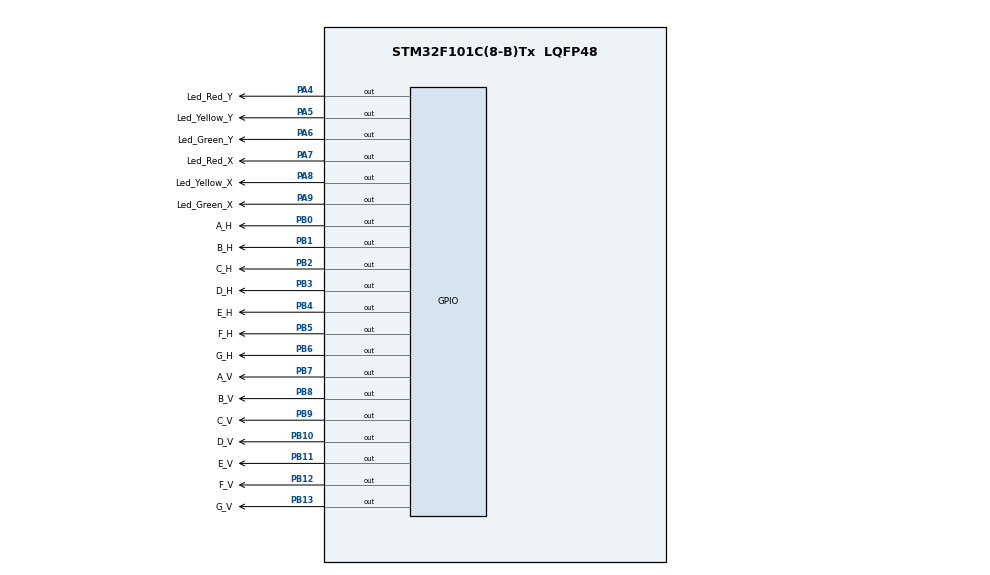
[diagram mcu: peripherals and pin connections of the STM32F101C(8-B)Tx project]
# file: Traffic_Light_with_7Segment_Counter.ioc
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Mcu.Family=STM32F1
Mcu.Name=STM32F101C(8-B)Tx
Mcu.Package=LQFP48
NVIC.PriorityGroup=NVIC_PRIORITYGROUP_4
PA4.GPIO_Label=Led_Red_Y
PA4.Signal=GPIO_Output
PA5.GPIO_Label=Led_Yellow_Y
PA5.Signal=GPIO_Output
PA6.GPIO_Label=Led_Green_Y
PA6.Signal=GPIO_Output
PA7.GPIO_Label=Led_Red_X
PA7.Signal=GPIO_Output
PA8.GPIO_Label=Led_Yellow_X
PA8.Signal=GPIO_Output
PA9.GPIO_Label=Led_Green_X
PA9.Signal=GPIO_Output
PB0.GPIO_Label=A_H
PB0.Signal=GPIO_Output
PB1.GPIO_Label=B_H
PB1.Signal=GPIO_Output
PB10.GPIO_Label=D_V
PB10.Signal=GPIO_Output
PB11.GPIO_Label=E_V
PB11.Signal=GPIO_Output
PB12.GPIO_Label=F_V
PB12.Signal=GPIO_Output
PB13.GPIO_Label=G_V
PB13.Signal=GPIO_Output
PB2.GPIO_Label=C_H
PB2.Signal=GPIO_Output
PB3.GPIO_Label=D_H
PB3.Signal=GPIO_Output
PB4.GPIO_Label=E_H
PB4.Signal=GPIO_Output
PB5.GPIO_Label=F_H
PB5.Signal=GPIO_Output
PB6.GPIO_Label=G_H
PB6.Signal=GPIO_Output
PB7.GPIO_Label=A_V
PB7.Signal=GPIO_Output
PB8.GPIO_Label=B_V
PB8.Signal=GPIO_Output
PB9.GPIO_Label=C_V
PB9.Signal=GPIO_Output
ProjectManager.HeapSize=0x200
ProjectManager.StackSize=0x400
ProjectManager.TargetToolchain=STM32CubeIDE
RCC.APB1Freq_Value=8000000
RCC.APB2Freq_Value=8000000
board=custom

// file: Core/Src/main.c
/* USER CODE BEGIN Header */
/**
  ******************************************************************************
  * @file           : main.c
  * @brief          : Main program body
  ******************************************************************************
  * @attention
  *
  * Copyright (c) 2025 STMicroelectronics.
  * All rights reserved.
  *
  * This software is licensed under terms that can be found in the LICENSE file
  * in the root directory of this software component.
  * If no LICENSE file comes with this software, it is provided AS-IS.
  *
  ******************************************************************************
  */
/* USER CODE END Header */
#include "main.h"

/* USER CODE BEGIN Includes */
#include "control_Traffic_Light.h"
/* USER CODE END Includes */

void SystemClock_Config(void);
static void MX_GPIO_Init(void);

int main(void)
{

  /* MCU Configuration--------------------------------------------------------*/

  /* Reset of all peripherals, Initializes the Flash interface and the Systick. */
  HAL_Init();

  /* Configure the system clock */
  SystemClock_Config();

  /* Initialize all configured peripherals */
  MX_GPIO_Init();
  /* USER CODE BEGIN 2 */
  init_control_light();

  /* USER CODE END 2 */

  /* Infinite loop */
  while (1)
  {

    /* USER CODE BEGIN 3 */
	  control_4_light();
	  HAL_Delay(1000);
  }
  /* USER CODE END 3 */
}

void SystemClock_Config(void)
{
  RCC_OscInitTypeDef RCC_OscInitStruct = {0};
  RCC_ClkInitTypeDef RCC_ClkInitStruct = {0};

  /** Initializes the RCC Oscillators according to the specified parameters
  * in the RCC_OscInitTypeDef structure.
  */
  RCC_OscInitStruct.OscillatorType = RCC_OSCILLATORTYPE_HSI;
  RCC_OscInitStruct.HSIState = RCC_HSI_ON;
  RCC_OscInitStruct.HSICalibrationValue = RCC_HSICALIBRATION_DEFAULT;
  RCC_OscInitStruct.PLL.PLLState = RCC_PLL_NONE;
  if (HAL_RCC_OscConfig(&RCC_OscInitStruct) != HAL_OK)
  {
    Error_Handler();
  }

  /** Initializes the CPU, AHB and APB buses clocks
  */
  RCC_ClkInitStruct.ClockType = RCC_CLOCKTYPE_HCLK|RCC_CLOCKTYPE_SYSCLK
                              |RCC_CLOCKTYPE_PCLK1|RCC_CLOCKTYPE_PCLK2;
  RCC_ClkInitStruct.SYSCLKSource = RCC_SYSCLKSOURCE_HSI;
  RCC_ClkInitStruct.AHBCLKDivider = RCC_SYSCLK_DIV1;
  RCC_ClkInitStruct.APB1CLKDivider = RCC_HCLK_DIV1;
  RCC_ClkInitStruct.APB2CLKDivider = RCC_HCLK_DIV1;

  if (HAL_RCC_ClockConfig(&RCC_ClkInitStruct, FLASH_LATENCY_0) != HAL_OK)
  {
    Error_Handler();
  }
}

static void MX_GPIO_Init(void)
{
  GPIO_InitTypeDef GPIO_InitStruct = {0};

  /* GPIO Ports Clock Enable */
  __HAL_RCC_GPIOA_CLK_ENABLE();
  __HAL_RCC_GPIOB_CLK_ENABLE();

  /*Configure GPIO pin Output Level */
  HAL_GPIO_WritePin(GPIOA, Led_Red_Y_Pin|Led_Yellow_Y_Pin|Led_Green_Y_Pin|Led_Red_X_Pin
                          |Led_Yellow_X_Pin|Led_Green_X_Pin, GPIO_PIN_RESET);

  /*Configure GPIO pin Output Level */
  HAL_GPIO_WritePin(GPIOB, A_H_Pin|B_H_Pin|C_H_Pin|D_V_Pin
                          |E_V_Pin|F_V_Pin|G_V_Pin|D_H_Pin
                          |E_H_Pin|F_H_Pin|G_H_Pin|A_V_Pin
                          |B_V_Pin|C_V_Pin, GPIO_PIN_RESET);

  /*Configure GPIO pins : Led_Red_Y_Pin Led_Yellow_Y_Pin Led_Green_Y_Pin Led_Red_X_Pin
                           Led_Yellow_X_Pin Led_Green_X_Pin */
  GPIO_InitStruct.Pin = Led_Red_Y_Pin|Led_Yellow_Y_Pin|Led_Green_Y_Pin|Led_Red_X_Pin
                          |Led_Yellow_X_Pin|Led_Green_X_Pin;
  GPIO_InitStruct.Mode = GPIO_MODE_OUTPUT_PP;
  GPIO_InitStruct.Pull = GPIO_NOPULL;
  GPIO_InitStruct.Speed = GPIO_SPEED_FREQ_LOW;
  HAL_GPIO_Init(GPIOA, &GPIO_InitStruct);

  /*Configure GPIO pins : A_H_Pin B_H_Pin C_H_Pin D_V_Pin
                           E_V_Pin F_V_Pin G_V_Pin D_H_Pin
                           E_H_Pin F_H_Pin G_H_Pin A_V_Pin
                           B_V_Pin C_V_Pin */
  GPIO_InitStruct.Pin = A_H_Pin|B_H_Pin|C_H_Pin|D_V_Pin
                          |E_V_Pin|F_V_Pin|G_V_Pin|D_H_Pin
                          |E_H_Pin|F_H_Pin|G_H_Pin|A_V_Pin
                          |B_V_Pin|C_V_Pin;
  GPIO_InitStruct.Mode = GPIO_MODE_OUTPUT_PP;
  GPIO_InitStruct.Pull = GPIO_NOPULL;
  GPIO_InitStruct.Speed = GPIO_SPEED_FREQ_LOW;
  HAL_GPIO_Init(GPIOB, &GPIO_InitStruct);

}

void Error_Handler(void)
{
  __disable_irq();
  while (1)
  {
  }
}
